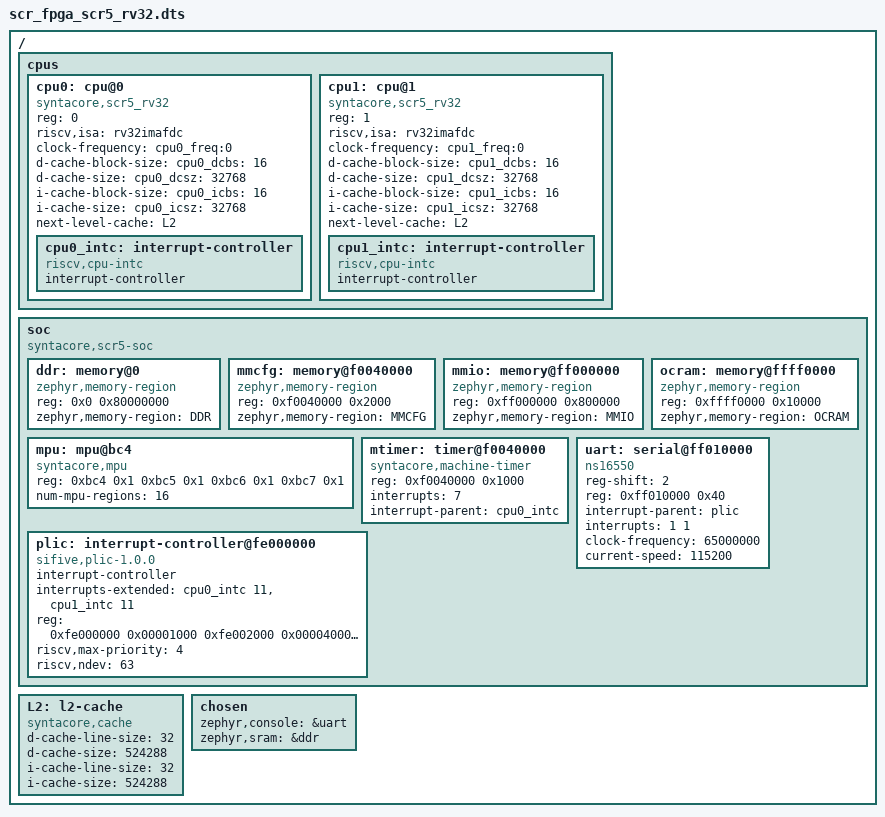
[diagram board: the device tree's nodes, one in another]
/*
 * Copyright (C) 2025, Syntacore Ltd.
 *
 * Licensed under the Apache License, Version 2.0 (the "License");
 * you may not use this file except in compliance with the License.
 * You may obtain a copy of the License at
 *     http://www.apache.org/licenses/LICENSE-2.0
 * Unless required by applicable law or agreed to in writing, software
 * distributed under the License is distributed on an "AS IS" BASIS,
 * WITHOUT WARRANTIES OR CONDITIONS OF ANY KIND, either express or implied.
 * See the License for the specific language governing permissions and
 * limitations under the License.
 */

#include <mem.h>

/dts-v1/;

/ {
	#address-cells = <1>;
	#size-cells = <1>;
	cpus {
		#address-cells = <1>;
		#size-cells = <0>;
		cpu0: cpu@0 {
			device_type = cpu0_devtype:"cpu";
			reg = <0>;
			status = "okay";
			compatible = "syntacore,scr5_rv32","riscv";
			riscv,isa = "rv32imafdc";
			clock-frequency = <cpu0_freq:0>;

			d-cache-block-size = <cpu0_dcbs: 16>;
			d-cache-size = <cpu0_dcsz: 32768>;
			i-cache-block-size = <cpu0_icbs: 16>;
			i-cache-size = <cpu0_icsz: 32768>;
			
			next-level-cache = <&L2>;
			
			cpu0_intc: interrupt-controller {
				compatible = "riscv,cpu-intc";
				#interrupt-cells = <1>;
				interrupt-controller;
			};
		};
		
		cpu1: cpu@1 {
			device_type = cpu1_devtype:"cpu";
			reg = <1>;
			status = "okay";
			compatible = "syntacore,scr5_rv32","riscv";
			riscv,isa = "rv32imafdc";
			clock-frequency = <cpu1_freq:0>;

			d-cache-block-size = <cpu1_dcbs: 16>;
			d-cache-size = <cpu1_dcsz: 32768>;
			i-cache-block-size = <cpu1_icbs: 16>;
			i-cache-size = <cpu1_icsz: 32768>;
			
			next-level-cache = <&L2>;
			
			cpu1_intc: interrupt-controller {
				compatible = "riscv,cpu-intc";
				#interrupt-cells = <1>;
				interrupt-controller;
			};
		};
	};

	soc {
		#address-cells = <1>;
		#size-cells = <1>;
		compatible = "syntacore,scr5-soc";
		ranges;
		
		ddr: memory@0 {
			compatible = "zephyr,memory-region";
			reg = <0x0 0x80000000>;
			zephyr,memory-region = "DDR";
		};
		
		mmcfg: memory@f0040000 {
			compatible = "zephyr,memory-region";
			reg = <0xf0040000 0x2000>;
			zephyr,memory-region = "MMCFG";
		};
		
		mmio: memory@ff000000 {
			compatible = "zephyr,memory-region";
			reg = <0xff000000 0x800000>;
			zephyr,memory-region = "MMIO";
		};
		
		ocram: memory@ffff0000 {
			compatible = "zephyr,memory-region";
			reg = <0xffff0000 0x10000>;
			zephyr,memory-region = "OCRAM";
		};
		
		mpu: mpu@bc4 {
			compatible = "syntacore,mpu";
			reg = <0xbc4 0x1
				0xbc5 0x1
				0xbc6 0x1
				0xbc7 0x1>;
			reg-names = "select", "control", "address", "mask";
			num-mpu-regions = <16>;
		};
		
		mtimer: timer@f0040000 {
			compatible = "syntacore,machine-timer";
			reg = <0xf0040000 0x1000>;
			interrupts = <7>;
			interrupt-parent = <&cpu0_intc>;
		};
		
		plic: interrupt-controller@fe000000 {
			#interrupt-cells = <2>;
			compatible = "sifive,plic-1.0.0", "riscv,plic0";
			interrupt-controller;
			interrupts-extended = <&cpu0_intc 11
				&cpu1_intc 11>;	

			reg = <0xfe000000 0x00001000
				0xfe002000  0x00004000
				0xfe200000  0x00040000 >;
			reg-names = "prio", "irq_en", "reg";

			riscv,max-priority = <4>;
			riscv,ndev = <63>;
		};
		
		uart: serial@ff010000 {
			compatible = "ns16550";
			reg-shift = < 2 >;
			reg = <0xff010000 0x40>;
			interrupt-parent = <&plic>;
			interrupts = <1 1>; // IRQ PRIO
			clock-frequency = <65000000>;
			current-speed = <115200>;
			status = "okay";
		};
	};
	
	L2: l2-cache {
		compatible = "syntacore,cache";
		d-cache-line-size = <32>;
		d-cache-size = <524288>;
		i-cache-line-size = <32>;
		i-cache-size = <524288>;
	};
	
	chosen {
		zephyr,console = &uart;
		/* Use DDR as SRAM by default */
		zephyr,sram = &ddr;
	};
};
